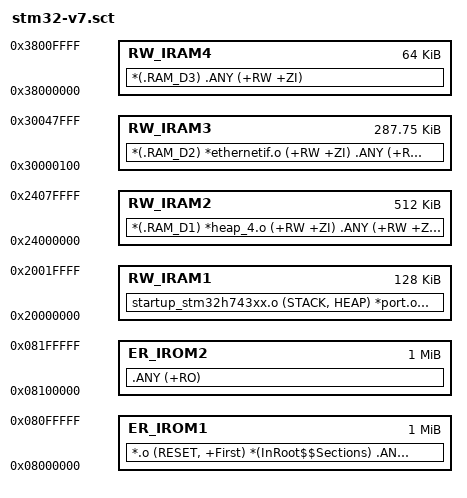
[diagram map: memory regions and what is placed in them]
; DSO_V8.5+ETH: DTCM stack only, D1/D2/D3 with .ANY cascade
LR_IROM1 0x08000000 0x00100000 {
  ER_IROM1 0x08000000 0x00100000 {
   *.o (RESET, +First) *(InRoot$$Sections) .ANY (+RO) .ANY (+XO)
  }
  RW_IRAM1 0x20000000 0x00020000 { startup_stm32h743xx.o (STACK, HEAP) *port.o (+RW +ZI) }
  RW_IRAM2 0x24000000 0x00080000 { *(.RAM_D1) *heap_4.o (+RW +ZI) .ANY (+RW +ZI) }
  RW_IRAM3 0x30000100 0x00047F00 { *(.RAM_D2) *ethernetif.o (+RW +ZI) .ANY (+RW +ZI) }
  RW_IRAM4 0x38000000 0x00010000 { *(.RAM_D3) .ANY (+RW +ZI) }
}
LR_IROM2 0x08100000 0x00100000 { ER_IROM2 0x08100000 0x00100000 { .ANY (+RO) } }
